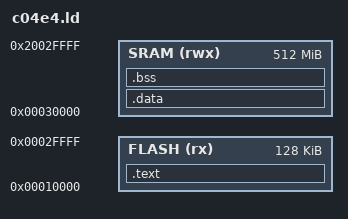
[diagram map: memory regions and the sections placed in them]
/******************************************************************************
 *
 * c04e4.ld - Linker configuration file for add.
 *
 * Copyright (c) 2012 Roger Ye.  All rights reserved.
 * Software License Agreement
 * 
 * 
 * THIS SOFTWARE IS PROVIDED "AS IS" AND WITH ALL FAULTS.
 * NO WARRANTIES, WHETHER EXPRESS, IMPLIED OR STATUTORY, INCLUDING, BUT
 * NOT LIMITED TO, IMPLIED WARRANTIES OF MERCHANTABILITY AND FITNESS FOR
 * A PARTICULAR PURPOSE APPLY TO THIS SOFTWARE. The AUTHOR SHALL NOT, UNDER
 * ANY CIRCUMSTANCES, BE LIABLE FOR SPECIAL, INCIDENTAL, OR CONSEQUENTIAL
 * DAMAGES, FOR ANY REASON WHATSOEVER.
 *
 *****************************************************************************/

MEMORY
{
    FLASH (rx) : ORIGIN = 0x00010000, LENGTH = 128K
    SRAM (rwx) : ORIGIN = 0x00030000, LENGTH = 512M
}

SECTIONS
{
    .text :
    {
        _text = .;
        KEEP(*(.isr_vector))
        *(.text*)
        *(.rodata*)
        _etext = .;
    } > FLASH

    .data : AT(ADDR(.text) + SIZEOF(.text))
    {
        _data = .;
        *(vtable)
        *(.data*)
        _edata = .;
    } > SRAM

    .bss :
    {
        _bss = .;
        *(.bss*)
        *(COMMON)
        _ebss = .;
    } > SRAM
}
